# CPU_SAU register map
Vendor: Texas Instruments
Peripheral module from a debugger description file (folder CC26x4).
Registers are 32-bit, access per field, reset 0x0 unless marked. A register's access mark holds for its fields unless they carry their own. Offsets are as the file gives them; lines under a group give offsets from that group; [hi:lo] are bit positions; {n}, {i} and the like mark numbered series; 'fields as' and 'values as' point back to an identical list; <NAME> marks a mode.

## CPU_SAU — Cortex-M's Security Attribution Unit (SAU)
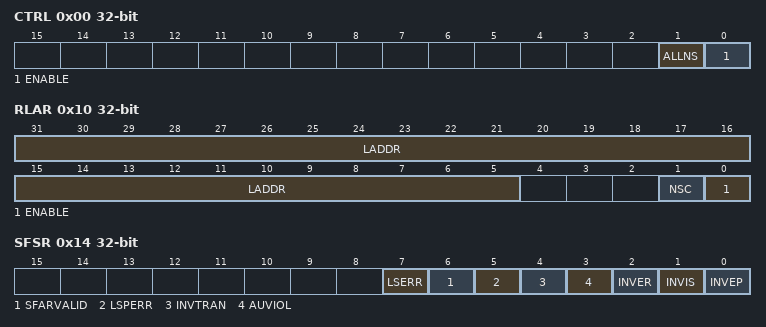
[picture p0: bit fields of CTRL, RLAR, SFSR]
0x00 CTRL — Allows enabling of the Security Attribution Unit
  [1] ALLNS rw — When SAU_CTRL.ENABLE is 0 this bit controls if the memory is marked as Non-secure or Secure
  [0] ENABLE rw — Enables the SAU
0x04 TYPE ro — Indicates the number of regions implemented by the Security Attribution Unit
  [7:0] SREGION — The number of implemented SAU regions
0x08 RNR — Selects the region currently accessed by SAU_RBAR and SAU_RLAR
  [7:0] REGION rw — Indicates the SAU region accessed by SAU_RBAR and SAU_RLAR
0x0C RBAR — Provides indirect read and write access to the base address of the currently selected SAU region
  [31:5] BADDR rw — Holds bits [31:5] of the base address for the selected SAU region
0x10 RLAR — Provides indirect read and write access to the limit address of the currently selected SAU region
  [31:5] LADDR rw — Holds bits [31:5] of the limit address for the selected SAU region
  [1] NSC rw — Controls whether Non-secure state is permitted to execute an SG instruction from this region
  [0] ENABLE rw — SAU region enable
0x14 SFSR — Provides information about any security related faults
  [7] LSERR rw — Sticky flag indicating that an error occurred during lazy state activation or deactivation
  [6] SFARVALID rw — This bit is set when the SFAR register contains a valid value. As with similar fields, such as BFSR.BFARVALID and MMFSR.MMARVALID, this bit can be cleared by other exceptions, such as BusFault
  [5] LSPERR rw — Stick flag indicating that an SAU or IDAU violation occurred during the lazy preservation of floating-point state
  [4] INVTRAN rw — Sticky flag indicating that an exception was raised due to a branch that was not flagged as being domain crossing causing a transition from Secure to Non-secure memory
  [3] AUVIOL rw — Sticky flag indicating that an attempt was made to access parts of the address space that are marked as Secure with NS-Req for the transaction set to Non-secure. This bit is not set if the violation occurred during lazy state preservation. See LSPERR
  [2] INVER rw — This can be caused by EXC_RETURN.DCRS being set to 0 when returning from an exception in the Non-secure state, or by EXC_RETURN.ES being set to 1 when returning from an exception in the Non-secure state
  [1] INVIS rw — This bit is set if the integrity signature in an exception stack frame is found to be invalid during the unstacking operation
  [0] INVEP rw — This bit is set if a function call from the Non-secure state or exception targets a non-SG instruction in the Secure state. This bit is also set if the target address is a SG instruction, but there is no matching SAU/IDAU region with the NSC flag set
0x18 SFAR rw — Shows the address of the memory location that caused a Security violation
  [31:0] ADDRESS — The address of an access that caused a attribution unit violation. This field is only valid when SFSR.SFARVALID is set. This allows the actual flip flops associated with this register to be shared with other fault address registers. If an implementation chooses to share the storage in this way, care must be taken to not leak Secure address information to the Non-secure state. One way of achieving this is to share the SFAR register with the MMFAR_S register, which is not accessible to the Non-secure state
